VERSION ""

NS_ :

BS_:
BU_: CAS GWS EGS
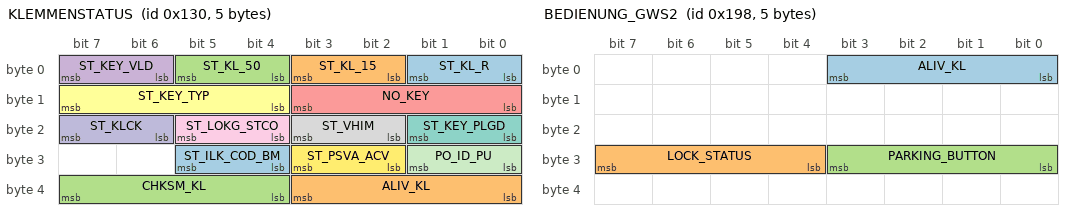
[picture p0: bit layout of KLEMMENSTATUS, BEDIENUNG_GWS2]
BO_ 304 KLEMMENSTATUS: 5 CAS
   SG_ ST_KL_R : 0|2@1+ (1,0) [0|0] "" CAS
   SG_ ST_KL_15 : 2|2@1+ (1,0) [0|0] "" CAS
   SG_ ST_KL_50 : 4|2@1+ (1,0) [0|0] "" CAS
   SG_ ST_KEY_VLD : 6|2@1+ (1,0) [0|0] "" CAS
   SG_ NO_KEY : 8|4@1+ (1,0) [0|0] "" CAS
   SG_ ST_KEY_TYP : 12|4@1+ (1,0) [0|0] "" CAS
   SG_ ST_KEY_PLGD : 16|2@1+ (1,0) [0|0] "" CAS
   SG_ ST_VHIM : 18|2@1+ (1,0) [0|0] "" CAS
   SG_ ST_LOKG_STCO : 20|2@1+ (1,0) [0|0] "" CAS
   SG_ ST_KLCK : 22|2@1+ (1,0) [0|0] "" CAS
   SG_ PO_ID_PU : 24|2@1+ (1,0) [0|0] "" CAS
   SG_ ST_PSVA_ACV : 26|2@1+ (1,0) [0|0] "" CAS
   SG_ ST_ILK_COD_BM : 28|2@1+ (1,0) [0|0] "" CAS
   SG_ ALIV_KL : 32|4@1+ (1,0) [0|14] "" CAS
   SG_ CHKSM_KL : 36|4@1+ (1,0) [0|15] "" CAS

BO_ 1246 NETZWERKMANAGEMENT_GWS: 8 GWS
   SG_ Byte0 : 0|8@1+ (1,0) [0|0] "" GWS

BO_ 408 BEDIENUNG_GWS2: 5 GWS
   SG_ ALIV_KL : 0|4@1+ (1,0) [0|14] "" Vector__XXX
   SG_ LOCK_STATUS : 28|4@1+ (1,0) [0|14] "" Vector__XXX
   SG_ PARKING_BUTTON : 24|4@1+ (1,0) [0|14] "" Vector__XXX

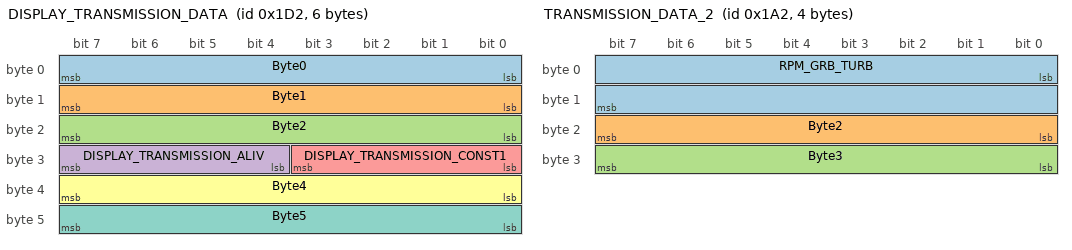
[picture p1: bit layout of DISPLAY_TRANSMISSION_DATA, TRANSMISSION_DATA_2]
BO_ 466 DISPLAY_TRANSMISSION_DATA: 6 EGS
   SG_ Byte0 : 0|8@1+ (1,0) [0|0] "" Vector__XXX
   SG_ Byte1 : 8|8@1+ (1,0) [0|0] "" Vector__XXX
   SG_ Byte2 : 16|8@1+ (1,0) [0|0] "" Vector__XXX
   SG_ DISPLAY_TRANSMISSION_ALIV : 28|4@1+ (1,0) [0|14] "" Vector__XXX
   SG_ DISPLAY_TRANSMISSION_CONST1 : 24|4@1+ (1,0) [0|14] "" EGS
   SG_ Byte4 : 32|8@1+ (1,0) [0|0] "" Vector__XXX
   SG_ Byte5 : 40|8@1+ (1,0) [0|0] "" Vector__XXX

BO_ 418 TRANSMISSION_DATA_2: 4 EGS
   SG_ RPM_GRB_TURB : 0|16@1+ (0.125,6) [0|8191.75] "1/min" EGS
   SG_ Byte2 : 16|8@1+ (1,0) [0|254] "" EGS
   SG_ Byte3 : 24|8@1+ (1,0) [0|254] "" EGS

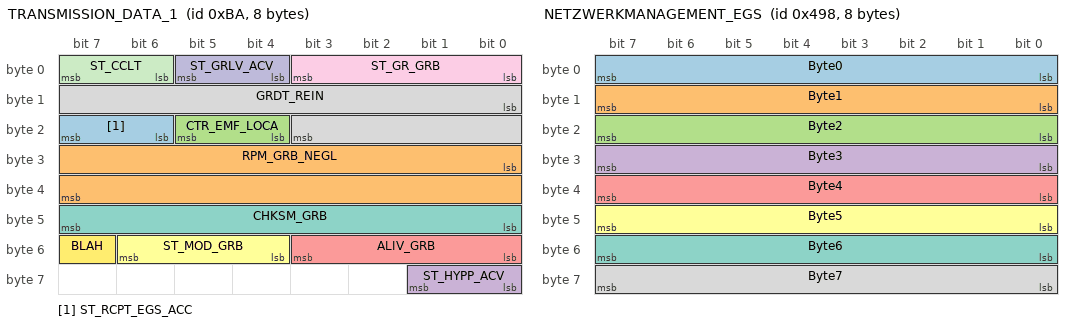
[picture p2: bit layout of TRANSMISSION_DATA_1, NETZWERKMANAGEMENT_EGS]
BO_ 186 TRANSMISSION_DATA_1: 8 EGS
   SG_ ST_RCPT_EGS_ACC : 22|2@1+ (1,0) [0|0] "" Vector__XXX
   SG_ RPM_GRB_NEGL : 24|16@1+ (0.125,0) [0|0] "1/min" Vector__XXX
   SG_ CTR_EMF_LOCA : 20|2@1+ (1,0) [0|0] "" Vector__XXX
   SG_ ST_HYPP_ACV : 56|2@1+ (1,0) [0|0] "" Vector__XXX
   SG_ ALIV_GRB : 48|4@1+ (1,0) [0|0] "" Vector__XXX
   SG_ ST_MOD_GRB : 52|3@1+ (1,0) [0|0] "" Vector__XXX
   SG_ CHKSM_GRB : 40|8@1+ (1,0) [0|0] "" Vector__XXX
   SG_ GRDT_REIN : 8|12@1+ (0.125,0) [0|0] "1/m" Vector__XXX
   SG_ ST_GR_GRB : 0|4@1+ (1,0) [0|0] "" Vector__XXX
   SG_ ST_GRLV_ACV : 4|2@1+ (1,0) [0|0] "" Vector__XXX
   SG_ ST_CCLT : 6|2@1+ (1,0) [0|0] "" Vector__XXX
   SG_ BLAH : 55|1@1+ (1,0) [0|0] "" Vector__XXX

BO_ 1176 NETZWERKMANAGEMENT_EGS: 8 EGS
   SG_ Byte0 : 0|8@1+ (1,0) [0|0] "" Vector__XXX
   SG_ Byte1 : 8|8@1+ (1,0) [0|0] "" Vector__XXX
   SG_ Byte2 : 16|8@1+ (1,0) [0|0] "" Vector__XXX
   SG_ Byte3 : 24|8@1+ (1,0) [0|0] "" Vector__XXX
   SG_ Byte4 : 32|8@1+ (1,0) [0|0] "" Vector__XXX
   SG_ Byte5 : 40|8@1+ (1,0) [0|0] "" Vector__XXX
   SG_ Byte6 : 48|8@1+ (1,0) [0|0] "" Vector__XXX
   SG_ Byte7 : 56|8@1+ (1,0) [0|0] "" Vector__XXX

BA_DEF_ BO_ "GenMsgBackgroundColor" STRING ;
BA_DEF_ BO_ "GenMsgForegroundColor" STRING ;
BA_DEF_DEF_ "GenMsgBackgroundColor" "#ffffff";
BA_DEF_DEF_ "GenMsgForegroundColor" "#000000";
CM_ SG_ 418 RPM_GRB_TURB "turbine_speed";
VAL_ 408 LOCK_STATUS 12 "unpressed" 9 "pressed";
VAL_ 408 PARKING_BUTTON 1 "pressed_1" 2 "pressed_2" 3 "pressed_3" 4 "pressed_4" 5 "pressed_5";
